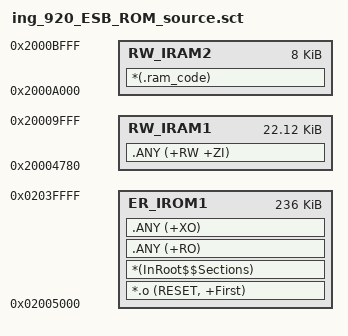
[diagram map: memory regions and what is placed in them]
; *************************************************************
; *** Scatter-Loading Description File generated by uVision ***
; *************************************************************

LR_IROM1 0x2005000 0x3B000  {    ; load region size_region
  ER_IROM1 0x2005000 0x3B000  {  ; load address = execution address
   *.o (RESET, +First)
   *(InRoot$$Sections)
   .ANY (+RO)
   .ANY (+XO)
  }
  RW_IRAM1 0x20004780 0x5880  {  ; RW data
    .ANY (+RW +ZI)
  }
  RW_IRAM2 0x2000a000 0x2000  {  ; RW data
   *(.ram_code)
  }
}

